# PIC18F05Q40 register map
Vendor: Microchip
Registers are 8-bit, read-write, reset 0x0 unless marked. A register's access mark holds for its fields unless they carry their own. Addresses are absolute, and some are shared; only a register's first bit layout is shown; [hi:lo] are bit positions.

## tmr_smt
0x300 SMT1TMRL
  [7:0] SMT1TMR
0x301 SMT1TMRH
  [7:0] SMT1TMR
0x302 SMT1TMRU
  [7:0] SMT1TMR
0x303 SMT1CPRL ro reset not defined — (power-on value xxxxxxxx)
  [7:0] SMT1CPR
0x304 SMT1CPRH ro reset not defined — (power-on value xxxxxxxx)
  [7:0] SMT1CPR
0x305 SMT1CPRU ro reset not defined — (power-on value xxxxxxxx)
  [7:0] SMT1CPR
0x306 SMT1CPWL ro reset not defined — (power-on value xxxxxxxx)
  [7:0] SMT1CPW
0x307 SMT1CPWH ro reset not defined — (power-on value xxxxxxxx)
  [7:0] SMT1CPW
0x308 SMT1CPWU ro reset not defined — (power-on value xxxxxxxx)
  [7:0] SMT1CPW
0x309 SMT1PRL reset 0xFF
  [7:0] SMT1PR
0x30A SMT1PRH reset 0xFF
  [7:0] SMT1PR
0x30B SMT1PRU reset 0xFF
  [7:0] SMT1PR
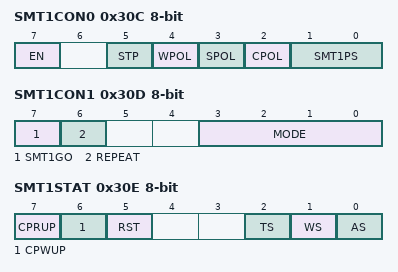
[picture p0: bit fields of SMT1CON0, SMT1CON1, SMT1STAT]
0x30C SMT1CON0
  [7] EN, [5] STP, [4] WPOL, [3] SPOL, [2] CPOL, [1:0] SMT1PS
0x30D SMT1CON1
  [7] SMT1GO, [6] REPEAT, [3:0] MODE
0x30E SMT1STAT
  [7] CPRUP, [6] CPWUP, [5] RST, [2] TS ro, [1] WS ro, [0] AS ro
0x30F SMT1CLK
  [3:0] CSEL
0x310 SMT1SIG
  [4:0] SSEL
0x311 SMT1WIN
  [4:0] WSEL

## tmr
0x312 TMR1L
0x313 TMR1H
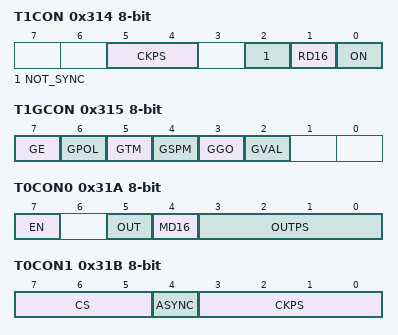
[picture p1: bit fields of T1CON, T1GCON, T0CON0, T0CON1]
0x314 T1CON
  [5:4] CKPS, [2] NOT_SYNC, [1] RD16, [0] ON
0x315 T1GCON reset not defined — (power-on value 00000x--)
  [7] GE, [6] GPOL, [5] GTM, [4] GSPM, [3] GGO, [2] GVAL ro
0x316 T1GATE
  [4:0] GSS
0x317 T1CLK
  [4:0] CS
0x318 TMR0L
0x319 TMR0H reset 0xFF
0x31A T0CON0
  [7] EN, [5] OUT ro, [4] MD16, [3:0] OUTPS
0x31B T0CON1
  [7:5] CS, [4] ASYNC, [3:0] CKPS
0x31C T2TMR — 8-bit period timer
  [7:0] TMR2
0x31D T2PR reset 0xFF
  [7:0] PR2
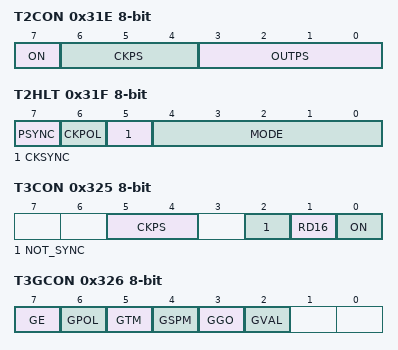
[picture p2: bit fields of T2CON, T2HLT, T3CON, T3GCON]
0x31E T2CON
  [7] ON, [6:4] CKPS, [3:0] OUTPS
0x31F T2HLT
  [7] PSYNC, [6] CKPOL, [5] CKSYNC, [4:0] MODE
0x320 T2CLKCON
  [3:0] CS
0x321 T2RST
  [4:0] RSEL
0x323 TMR3L
0x324 TMR3H
0x325 T3CON
  [5:4] CKPS, [2] NOT_SYNC, [1] RD16, [0] ON
0x326 T3GCON reset not defined — (power-on value 00000x--)
  [7] GE, [6] GPOL, [5] GTM, [4] GSPM, [3] GGO, [2] GVAL ro
0x327 T3GATE
  [4:0] GSS
0x328 T3CLK
  [4:0] CS
0x329 T4TMR — 8-bit period timer
  [7:0] TMR4
0x32A T4PR reset 0xFF
  [7:0] PR4
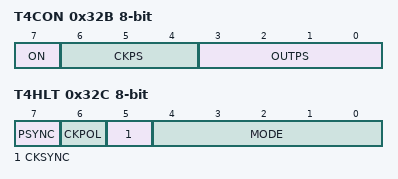
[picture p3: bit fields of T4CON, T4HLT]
0x32B T4CON
  [7] ON, [6:4] CKPS, [3:0] OUTPS
0x32C T4HLT
  [7] PSYNC, [6] CKPOL, [5] CKSYNC, [4:0] MODE
0x32D T4CLKCON
  [3:0] CS
0x32E T4RST
  [4:0] RSEL

## ccp
0x340 CCPR1L reset not defined — (power-on value xxxxxxxx)
  [7:0] RL
0x341 CCPR1H reset not defined — (power-on value xxxxxxxx)
  [7:0] RH
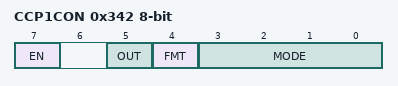
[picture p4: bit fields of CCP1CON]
0x342 CCP1CON
  [7] EN, [5] OUT ro, [4] FMT, [3:0] MODE
0x343 CCP1CAP
  [2:0] CTS

## math_progcrc
0x34E CRCDATAL
  [7:0] DATA
0x34F CRCDATAH
  [7:0] DATA
0x350 CRCDATAU
  [7:0] DATA
0x351 CRCDATAT
  [7:0] DATA
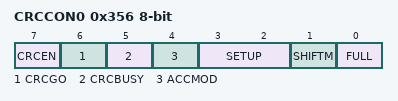
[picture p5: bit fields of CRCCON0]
0x356 CRCCON0
  [7] CRCEN, [6] CRCGO, [5] CRCBUSY ro, [4] ACCMOD, [3:2] SETUP, [1] SHIFTM, [0] FULL ro
0x357 CRCCON1
  [4:0] PLEN
0x358 CRCCON2
  [4:0] DLEN

## nvm_scan
0x35A SCANLADRL
  [7:0] LADR
0x35B SCANLADRH
  [7:0] LADR
0x35C SCANLADRU
  [5:0] LADR
0x35D SCANHADRL reset 0xFF
  [7:0] HADR
0x35E SCANHADRH reset 0xFF
  [7:0] HADR
0x35F SCANHADRU reset 0x3F
  [5:0] HADR
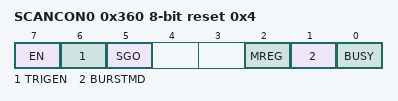
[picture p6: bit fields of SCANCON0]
0x360 SCANCON0 reset 0x4
  [7] EN, [6] TRIGEN, [5] SGO, [2] MREG, [1] BURSTMD, [0] BUSY
0x361 SCANTRIG
  [3:0] TSEL

## DOS_xxxx_Interrupts
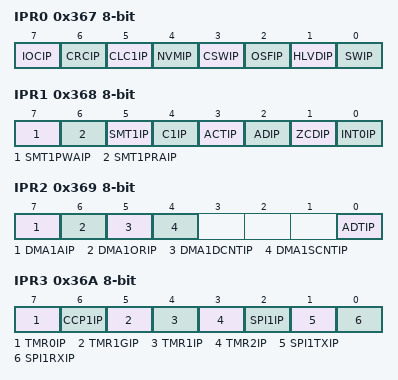
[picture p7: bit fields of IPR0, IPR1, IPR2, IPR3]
0x367 IPR0
  [7] IOCIP ro, [6] CRCIP, [5] CLC1IP, [4] NVMIP, [3] CSWIP, [2] OSFIP ro, [1] HLVDIP, [0] SWIP
0x368 IPR1
  [7] SMT1PWAIP, [6] SMT1PRAIP, [5] SMT1IP, [4] C1IP, [3] ACTIP, [2] ADIP, [1] ZCDIP, [0] INT0IP
0x369 IPR2
  [7] DMA1AIP, [6] DMA1ORIP, [5] DMA1DCNTIP, [4] DMA1SCNTIP, [0] ADTIP
0x36A IPR3
  [7] TMR0IP, [6] CCP1IP, [5] TMR1GIP, [4] TMR1IP, [3] TMR2IP, [2] SPI1IP ro, [1] SPI1TXIP ro, [0] SPI1RXIP ro
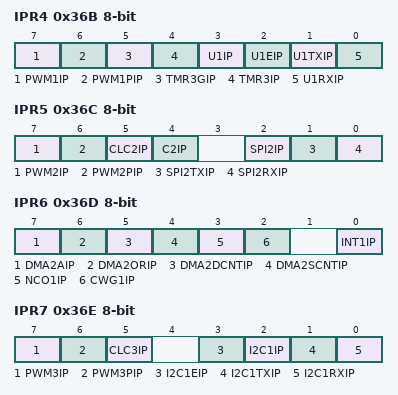
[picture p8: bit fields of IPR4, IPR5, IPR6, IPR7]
0x36B IPR4
  [7] PWM1IP ro, [6] PWM1PIP, [5] TMR3GIP, [4] TMR3IP, [3] U1IP ro, [2] U1EIP ro, [1] U1TXIP ro, [0] U1RXIP ro
0x36C IPR5
  [7] PWM2IP ro, [6] PWM2PIP, [5] CLC2IP, [4] C2IP, [2] SPI2IP ro, [1] SPI2TXIP ro, [0] SPI2RXIP ro
0x36D IPR6
  [7] DMA2AIP, [6] DMA2ORIP, [5] DMA2DCNTIP, [4] DMA2SCNTIP, [3] NCO1IP, [2] CWG1IP, [0] INT1IP
0x36E IPR7
  [7] PWM3IP ro, [6] PWM3PIP, [5] CLC3IP, [3] I2C1EIP ro, [2] I2C1IP ro, [1] I2C1TXIP ro, [0] I2C1RXIP ro
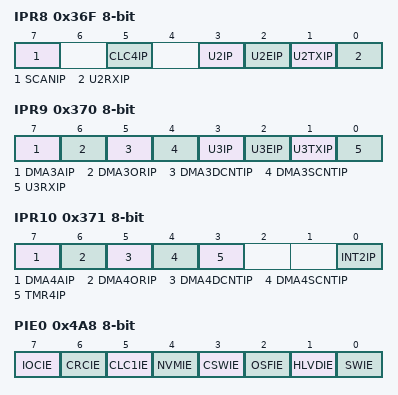
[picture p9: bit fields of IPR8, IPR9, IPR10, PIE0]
0x36F IPR8
  [7] SCANIP, [5] CLC4IP, [3] U2IP, [2] U2EIP, [1] U2TXIP, [0] U2RXIP
0x370 IPR9
  [7] DMA3AIP, [6] DMA3ORIP, [5] DMA3DCNTIP, [4] DMA3SCNTIP, [3] U3IP, [2] U3EIP, [1] U3TXIP, [0] U3RXIP
0x371 IPR10
  [7] DMA4AIP, [6] DMA4ORIP, [5] DMA4DCNTIP, [4] DMA4SCNTIP, [3] TMR4IP, [0] INT2IP
0x4A8 PIE0
  [7] IOCIE ro, [6] CRCIE, [5] CLC1IE, [4] NVMIE, [3] CSWIE, [2] OSFIE ro, [1] HLVDIE, [0] SWIE
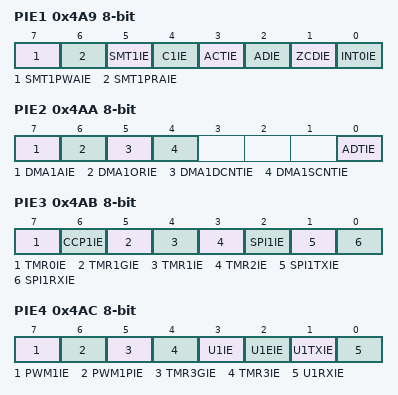
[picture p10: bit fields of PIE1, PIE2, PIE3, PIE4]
0x4A9 PIE1
  [7] SMT1PWAIE, [6] SMT1PRAIE, [5] SMT1IE, [4] C1IE, [3] ACTIE, [2] ADIE, [1] ZCDIE, [0] INT0IE
0x4AA PIE2
  [7] DMA1AIE, [6] DMA1ORIE, [5] DMA1DCNTIE, [4] DMA1SCNTIE, [0] ADTIE
0x4AB PIE3
  [7] TMR0IE, [6] CCP1IE, [5] TMR1GIE, [4] TMR1IE, [3] TMR2IE, [2] SPI1IE ro, [1] SPI1TXIE ro, [0] SPI1RXIE ro
0x4AC PIE4
  [7] PWM1IE ro, [6] PWM1PIE, [5] TMR3GIE, [4] TMR3IE, [3] U1IE ro, [2] U1EIE ro, [1] U1TXIE ro, [0] U1RXIE ro
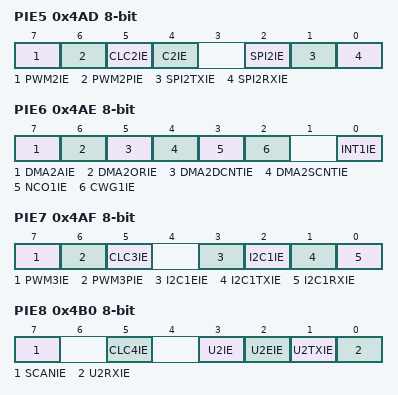
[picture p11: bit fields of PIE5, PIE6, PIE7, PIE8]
0x4AD PIE5
  [7] PWM2IE ro, [6] PWM2PIE, [5] CLC2IE, [4] C2IE, [2] SPI2IE ro, [1] SPI2TXIE ro, [0] SPI2RXIE ro
0x4AE PIE6
  [7] DMA2AIE, [6] DMA2ORIE, [5] DMA2DCNTIE, [4] DMA2SCNTIE, [3] NCO1IE, [2] CWG1IE, [0] INT1IE
0x4AF PIE7
  [7] PWM3IE ro, [6] PWM3PIE, [5] CLC3IE, [3] I2C1EIE ro, [2] I2C1IE ro, [1] I2C1TXIE ro, [0] I2C1RXIE ro
0x4B0 PIE8
  [7] SCANIE, [5] CLC4IE, [3] U2IE, [2] U2EIE, [1] U2TXIE, [0] U2RXIE
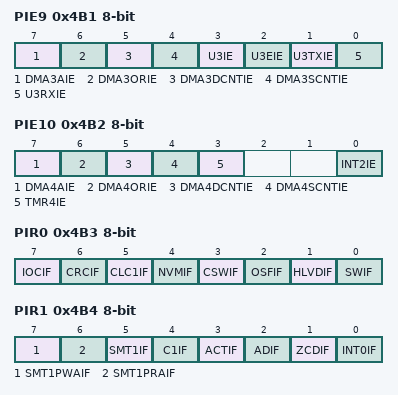
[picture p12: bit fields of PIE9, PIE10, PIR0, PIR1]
0x4B1 PIE9
  [7] DMA3AIE, [6] DMA3ORIE, [5] DMA3DCNTIE, [4] DMA3SCNTIE, [3] U3IE, [2] U3EIE, [1] U3TXIE, [0] U3RXIE
0x4B2 PIE10
  [7] DMA4AIE, [6] DMA4ORIE, [5] DMA4DCNTIE, [4] DMA4SCNTIE, [3] TMR4IE, [0] INT2IE
0x4B3 PIR0
  [7] IOCIF ro, [6] CRCIF, [5] CLC1IF, [4] NVMIF, [3] CSWIF, [2] OSFIF ro, [1] HLVDIF, [0] SWIF
0x4B4 PIR1
  [7] SMT1PWAIF, [6] SMT1PRAIF, [5] SMT1IF, [4] C1IF, [3] ACTIF, [2] ADIF, [1] ZCDIF, [0] INT0IF
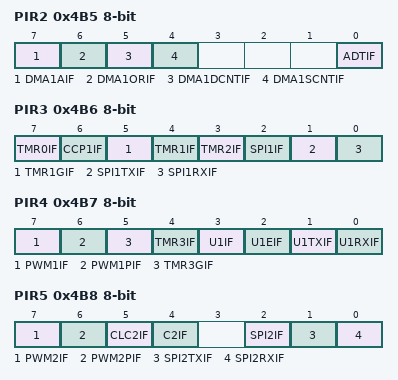
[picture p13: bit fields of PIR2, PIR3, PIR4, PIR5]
0x4B5 PIR2
  [7] DMA1AIF, [6] DMA1ORIF, [5] DMA1DCNTIF, [4] DMA1SCNTIF, [0] ADTIF
0x4B6 PIR3
  [7] TMR0IF, [6] CCP1IF, [5] TMR1GIF, [4] TMR1IF, [3] TMR2IF, [2] SPI1IF ro, [1] SPI1TXIF ro, [0] SPI1RXIF ro
0x4B7 PIR4
  [7] PWM1IF ro, [6] PWM1PIF, [5] TMR3GIF, [4] TMR3IF, [3] U1IF ro, [2] U1EIF ro, [1] U1TXIF ro, [0] U1RXIF ro
0x4B8 PIR5
  [7] PWM2IF ro, [6] PWM2PIF, [5] CLC2IF, [4] C2IF, [2] SPI2IF ro, [1] SPI2TXIF ro, [0] SPI2RXIF ro
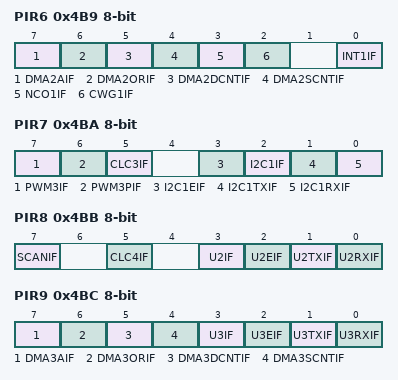
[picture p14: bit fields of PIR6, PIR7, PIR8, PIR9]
0x4B9 PIR6
  [7] DMA2AIF, [6] DMA2ORIF, [5] DMA2DCNTIF, [4] DMA2SCNTIF, [3] NCO1IF, [2] CWG1IF, [0] INT1IF
0x4BA PIR7
  [7] PWM3IF ro, [6] PWM3PIF, [5] CLC3IF, [3] I2C1EIF ro, [2] I2C1IF ro, [1] I2C1TXIF ro, [0] I2C1RXIF ro
0x4BB PIR8
  [7] SCANIF, [5] CLC4IF, [3] U2IF, [2] U2EIF, [1] U2TXIF, [0] U2RXIF
0x4BC PIR9
  [7] DMA3AIF, [6] DMA3ORIF, [5] DMA3DCNTIF, [4] DMA3SCNTIF, [3] U3IF, [2] U3EIF, [1] U3TXIF, [0] U3RXIF
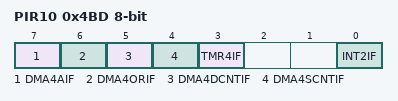
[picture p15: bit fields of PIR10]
0x4BD PIR10
  [7] DMA4AIF, [6] DMA4ORIF, [5] DMA4DCNTIF, [4] DMA4SCNTIF, [3] TMR4IF, [0] INT2IF
